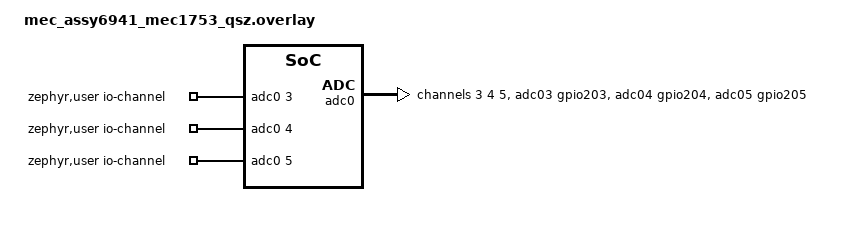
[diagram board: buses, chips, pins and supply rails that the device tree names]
/*
 * Copyright (c) 2026 Microchip Technology Inc.
 * SPDX-License-Identifier: Apache-2.0
 *
 */

#include <zephyr/dt-bindings/adc/adc.h>

/ {
	zephyr,user {
		io-channels = <&adc0 3>, <&adc0 4>, <&adc0 5>;
	};
};

&adc0 {
	compatible = "microchip,xec-adc";

	status = "okay";

	pinctrl-0 = <&adc03_gpio203 &adc04_gpio204 &adc05_gpio205>;
	pinctrl-names = "default";

	#address-cells = <1>;
	#size-cells = <0>;

	/*
	 * Close JP124 (10-11) (13-14), (16-17) to connect GPIO203, GPIO204 and adc05_gpio205
	 * to VCHIP_VREF_ADC (internal reference)
	 */

	channel@3 {
		reg = <3>;
		zephyr,gain = "ADC_GAIN_1";
		zephyr,reference = "ADC_REF_INTERNAL";
		zephyr,acquisition-time = <ADC_ACQ_TIME_DEFAULT>;
		zephyr,resolution = <10>;
	};

	channel@4 {
		reg = <4>;
		zephyr,gain = "ADC_GAIN_1";
		zephyr,reference = "ADC_REF_INTERNAL";
		zephyr,acquisition-time = <ADC_ACQ_TIME_DEFAULT>;
		zephyr,resolution = <10>;
	};

	channel@5 {
		reg = <5>;
		zephyr,gain = "ADC_GAIN_1";
		zephyr,reference = "ADC_REF_INTERNAL";
		zephyr,acquisition-time = <ADC_ACQ_TIME_DEFAULT>;
		zephyr,resolution = <10>;
	};
};
